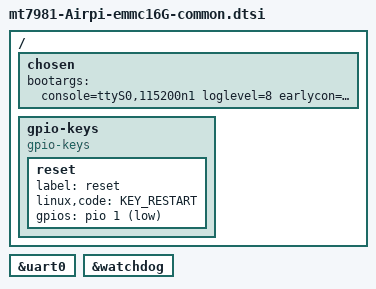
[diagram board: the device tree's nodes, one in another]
#include "mt7981.dtsi"

/ {
	chosen {
		bootargs = "console=ttyS0,115200n1 loglevel=8  \
				earlycon=uart8250,mmio32,0x11002000";
	};

	gpio-keys {
		compatible = "gpio-keys";
		reset {
			label = "reset";
			linux,code = <KEY_RESTART>;
			gpios = <&pio 1 GPIO_ACTIVE_LOW>;
		};
	};
};

&uart0 {
	status = "okay";
};

&watchdog {
	status = "okay";
};

